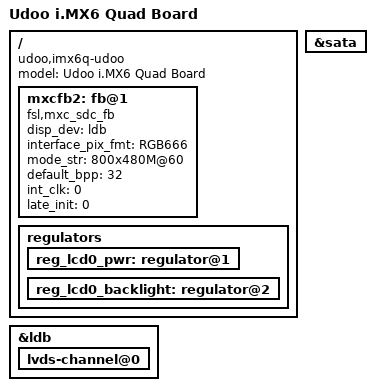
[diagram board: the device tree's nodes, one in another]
/*
 * Copyright 2013 Freescale Semiconductor, Inc.
 *
 * Author: Fabio Estevam <fabio.estevam@freescale.com>
 * Author: Ettore Chimenti <ettore.chimenti@udoo.org>
 *
 * This program is free software; you can redistribute it and/or modify
 * it under the terms of the GNU General Public License version 2 as
 * published by the Free Software Foundation.
 *
 */

/dts-v1/;
#include "imx6q.dtsi"
#include "imx6qdl-udoo.dtsi"

/ {
	model = "Udoo i.MX6 Quad Board";
	compatible = "udoo,imx6q-udoo", "fsl,imx6q";

	mxcfb2: fb@1 {
		compatible = "fsl,mxc_sdc_fb";
		disp_dev = "ldb";
		interface_pix_fmt = "RGB666";
		mode_str = "800x480M@60";
		default_bpp = <32>;
		int_clk = <0>;
		late_init = <0>;
		status = "okay";
	};
	
	regulators {
		reg_lcd0_pwr: regulator@1 {
			status = "okay";
		};

		reg_lcd0_backlight: regulator@2 {
			status = "okay";
		};
	};
};

&sata {
	status = "okay";
};

&ldb {
	status = "okay";

	lvds-channel@0 {
		status = "okay";
	};
};
